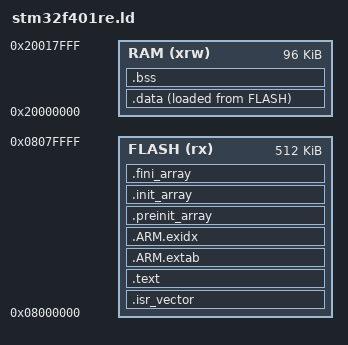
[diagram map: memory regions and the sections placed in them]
/*
 * Linker script for STM32F401RET6
 * 512K Flash, 96K RAM
 */

ENTRY(Reset_Handler)

MEMORY
{
  FLASH (rx) : ORIGIN = 0x08000000, LENGTH = 512K
  RAM (xrw)  : ORIGIN = 0x20000000, LENGTH = 96K
}

_estack = ORIGIN(RAM) + LENGTH(RAM); /* Highest address of the user mode stack */

SECTIONS
{
  /* The startup code goes first into FLASH */
  .isr_vector :
  {
    . = ALIGN(4);
    KEEP(*(.isr_vector)) /* Startup code */
    . = ALIGN(4);
  } >FLASH

  /* The program code and other data goes into FLASH */
  .text :
  {
    . = ALIGN(4);
    *(.text)           /* .text sections (code) */
    *(.text*)          /* .text* sections (code) */
    *(.rodata)         /* .rodata sections (constants, strings, etc.) */
    *(.rodata*)        /* .rodata* sections (constants, strings, etc.) */

    KEEP (*(.init))    /* glue crti.o prologue + crtn.o epilogue into _init */
    KEEP (*(.fini))    /* same for _fini */

    . = ALIGN(4);
    _etext = .;        /* define a global symbols at end of code */
  } >FLASH

  .ARM.extab : { *(.ARM.extab* .gnu.linkonce.armextab.*) } >FLASH
  .ARM.exidx :
  {
    __exidx_start = .;
    *(.ARM.exidx*)
    __exidx_end = .;
  } >FLASH

  .preinit_array :
  {
    PROVIDE_HIDDEN (__preinit_array_start = .);
    KEEP (*(.preinit_array*))
    PROVIDE_HIDDEN (__preinit_array_end = .);
  } >FLASH

  .init_array :
  {
    PROVIDE_HIDDEN (__init_array_start = .);
    KEEP (*(SORT(.init_array.*)))
    KEEP (*(.init_array*))
    PROVIDE_HIDDEN (__init_array_end = .);
  } >FLASH

  .fini_array :
  {
    PROVIDE_HIDDEN (__fini_array_start = .);
    KEEP (*(SORT(.fini_array.*)))
    KEEP (*(.fini_array*))
    PROVIDE_HIDDEN (__fini_array_end = .);
  } >FLASH

  /* used by the startup to initialize data */
  _sidata = LOADADDR(.data);

  /* Initialized data sections goes into RAM, load LMA copy after code */
  .data : 
  {
    . = ALIGN(4);
    _sdata = .;        /* create a global symbol at data start */
    *(.data)           /* .data sections */
    *(.data*)          /* .data* sections */
    . = ALIGN(4);
    _edata = .;        /* define a global symbol at data end */
  } >RAM AT> FLASH

  /* Uninitialized data section */
  .bss :
  {
    . = ALIGN(4);
    _sbss = .;         /* define a global symbol at bss start */
    *(.bss)
    *(.bss*)
    *(COMMON)
    . = ALIGN(4);
    _ebss = .;         /* define a global symbol at bss end */
  } >RAM
}
